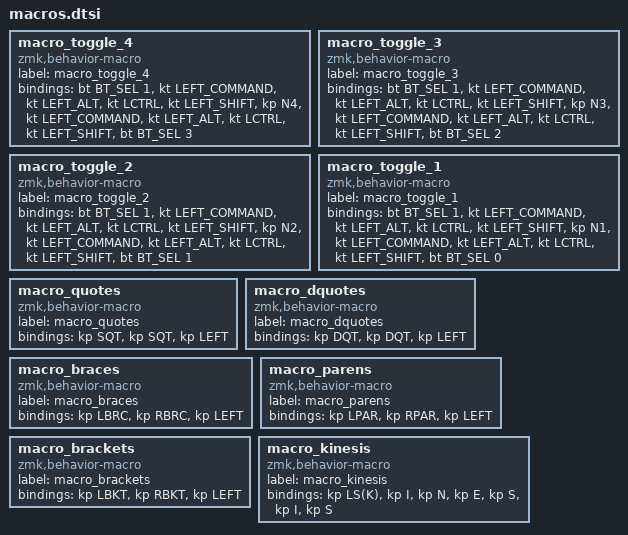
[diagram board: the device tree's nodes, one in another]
macro_toggle_4: macro_toggle_4{
compatible = "zmk,behavior-macro";
label = "macro_toggle_4";
#binding-cells = <0>;
bindings = <&bt BT_SEL 1>, <&kt LEFT_COMMAND>, <&kt LEFT_ALT>, <&kt LCTRL>, <&kt LEFT_SHIFT>, <&kp N4>, <&kt LEFT_COMMAND>, <&kt LEFT_ALT>, <&kt LCTRL>, <&kt LEFT_SHIFT>, <&bt BT_SEL 3>;
};
macro_toggle_3: macro_toggle_3{
compatible = "zmk,behavior-macro";
label = "macro_toggle_3";
#binding-cells = <0>;
bindings = <&bt BT_SEL 1>, <&kt LEFT_COMMAND>, <&kt LEFT_ALT>, <&kt LCTRL>, <&kt LEFT_SHIFT>, <&kp N3>, <&kt LEFT_COMMAND>, <&kt LEFT_ALT>, <&kt LCTRL>, <&kt LEFT_SHIFT>, <&bt BT_SEL 2>;
};
macro_toggle_2: macro_toggle_2{
compatible = "zmk,behavior-macro";
label = "macro_toggle_2";
#binding-cells = <0>;
bindings = <&bt BT_SEL 1>, <&kt LEFT_COMMAND>, <&kt LEFT_ALT>, <&kt LCTRL>, <&kt LEFT_SHIFT>, <&kp N2>, <&kt LEFT_COMMAND>, <&kt LEFT_ALT>, <&kt LCTRL>, <&kt LEFT_SHIFT>, <&bt BT_SEL 1>;
};
macro_toggle_1: macro_toggle_1{
compatible = "zmk,behavior-macro";
label = "macro_toggle_1";
#binding-cells = <0>;
bindings = <&bt BT_SEL 1>, <&kt LEFT_COMMAND>, <&kt LEFT_ALT>, <&kt LCTRL>, <&kt LEFT_SHIFT>, <&kp N1>, <&kt LEFT_COMMAND>, <&kt LEFT_ALT>, <&kt LCTRL>, <&kt LEFT_SHIFT>, <&bt BT_SEL 0>;
};
macro_quotes: macro_quotes{
compatible = "zmk,behavior-macro";
label = "macro_quotes";
#binding-cells = <0>;
bindings = <&kp SQT>, <&kp SQT>, <&kp LEFT>;
};
macro_dquotes: macro_dquotes{
compatible = "zmk,behavior-macro";
label = "macro_dquotes";
#binding-cells = <0>;
bindings = <&kp DQT>, <&kp DQT>, <&kp LEFT>;
};
macro_braces: macro_braces{
compatible = "zmk,behavior-macro";
label = "macro_braces";
#binding-cells = <0>;
bindings = <&kp LBRC>, <&kp RBRC>, <&kp LEFT>;
};
macro_parens: macro_parens{
compatible = "zmk,behavior-macro";
label = "macro_parens";
#binding-cells = <0>;
bindings = <&kp LPAR>, <&kp RPAR>, <&kp LEFT>;
};
macro_brackets: macro_brackets{
compatible = "zmk,behavior-macro";
label = "macro_brackets";
#binding-cells = <0>;
bindings = <&kp LBKT>, <&kp RBKT>, <&kp LEFT>;
};
macro_kinesis: macro_kinesis{
compatible = "zmk,behavior-macro";
label = "macro_kinesis";
#binding-cells = <0>;
bindings = <&kp LS(K)>, <&kp I>, <&kp N>, <&kp E>, <&kp S>, <&kp I>, <&kp S>;
};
